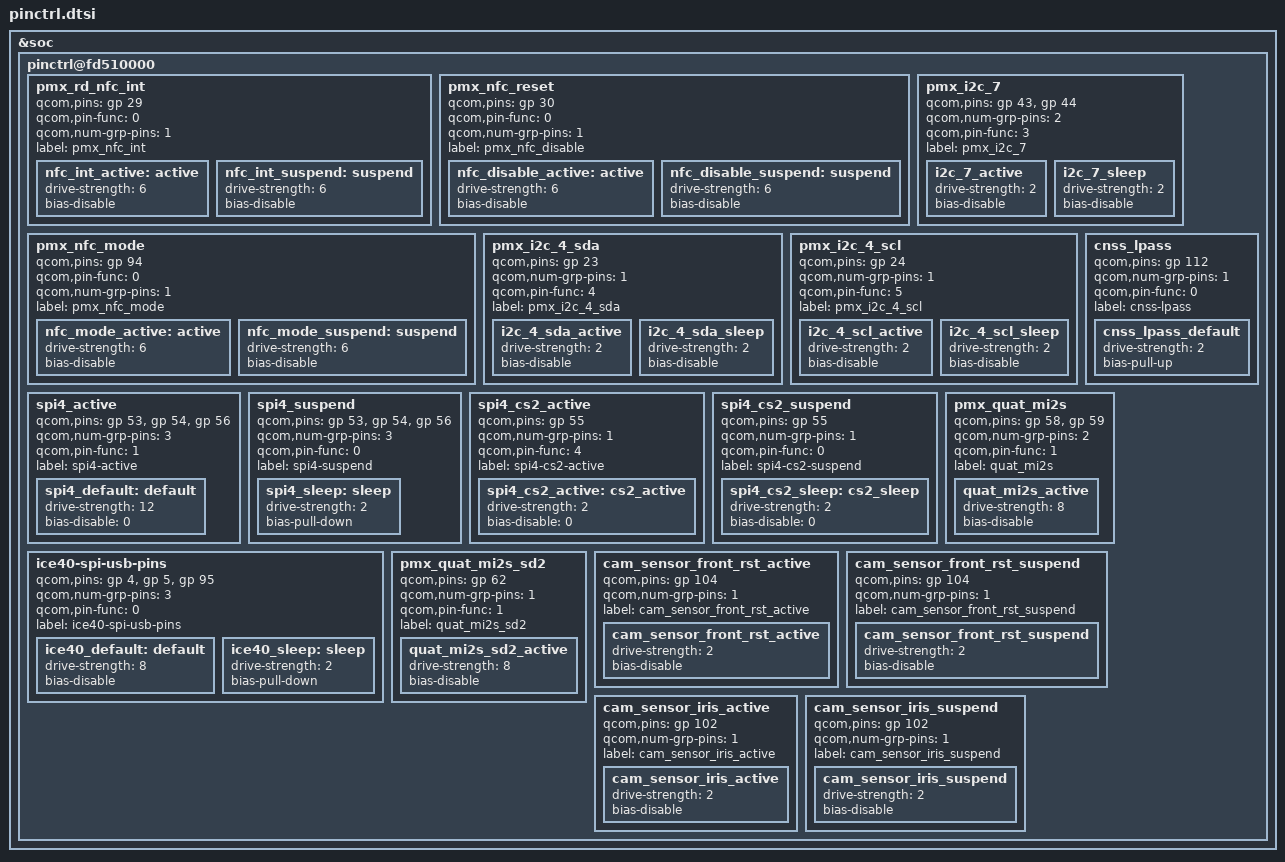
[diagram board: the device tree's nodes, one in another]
&soc {
	pinctrl@fd510000 {

        /* NFC Start */
		pmx_rd_nfc_int{
			qcom,pins = <&gp 29>;
			qcom,pin-func = <0>;
			qcom,num-grp-pins = <1>;
			label = "pmx_nfc_int";

			nfc_int_active: active {
				drive-strength = <6>;
				bias-disable;
			};

			nfc_int_suspend: suspend {
				drive-strength = <6>;
				bias-disable;
			};
		};

		pmx_nfc_reset{
			qcom,pins = <&gp 30>;
			qcom,pin-func = <0>;
			qcom,num-grp-pins = <1>;
			label = "pmx_nfc_disable";

			nfc_disable_active: active {
				drive-strength = <6>;
				bias-disable;
			};

			nfc_disable_suspend: suspend {
				drive-strength = <6>;
				bias-disable;
			};
		};

		pmx_nfc_mode{
			qcom,pins = <&gp 94>;
			qcom,pin-func = <0>;
			qcom,num-grp-pins = <1>;
			label = "pmx_nfc_mode";

			nfc_mode_active: active {
				drive-strength = <6>;
				bias-disable;
			};

			nfc_mode_suspend: suspend {
				drive-strength = <6>;
				bias-disable;
			};
		};
        /* NFC End */

		pmx_i2c_7 {
			qcom,pins = <&gp 43>, <&gp 44>; /* SDA, SCL — BLSP2 I2C1 */
			qcom,num-grp-pins = <2>;
			qcom,pin-func = <3>;
			label = "pmx_i2c_7";
	
			i2c_7_active: i2c_7_active {
				drive-strength = <2>;
				bias-disable;
			};
	
			i2c_7_sleep: i2c_7_sleep {
				drive-strength = <2>;
				bias-disable;
			};
		};

		/*
		 * IMU / mag / baro on BLSP1 QUP5 (mainline blsp1_i2c5).
		 * Unlike GPIO 27/28 and 43/44, these two pins do not share
		 * the same mux index: 23 is func 4, 24 is func 5.
		 * pin-func 3 here is UART/SPI and the chips never ACK.
		 */
		pmx_i2c_4_sda {
			qcom,pins = <&gp 23>;
			qcom,num-grp-pins = <1>;
			qcom,pin-func = <4>;
			label = "pmx_i2c_4_sda";

			i2c_4_sda_active: i2c_4_sda_active {
				drive-strength = <2>;
				bias-disable;
			};

			i2c_4_sda_sleep: i2c_4_sda_sleep {
				drive-strength = <2>;
				bias-disable;
			};
		};

		pmx_i2c_4_scl {
			qcom,pins = <&gp 24>;
			qcom,num-grp-pins = <1>;
			qcom,pin-func = <5>;
			label = "pmx_i2c_4_scl";

			i2c_4_scl_active: i2c_4_scl_active {
				drive-strength = <2>;
				bias-disable;
			};

			i2c_4_scl_sleep: i2c_4_scl_sleep {
				drive-strength = <2>;
				bias-disable;
			};
		};
		cnss_lpass: cnss_lpass {
			qcom,pins = <&gp 112>;
			qcom,num-grp-pins = <1>;
			qcom,pin-func = <0>;
			label = "cnss-lpass";
			/* default state */
			cnss_lpass_default: cnss_lpass_default {
				drive-strength = <2>;
				bias-pull-up;
			};
		};
		
		spi4_active {
			/* MOSI, MISO, CLK */
			qcom,pins = <&gp 53>, <&gp 54>, <&gp 56>;
			qcom,num-grp-pins = <3>;
			qcom,pin-func = <1>;
			label = "spi4-active";
			/* active state */
			spi4_default: default {
				drive-strength = <12>; /* 12 MA */
				bias-disable = <0>; /* No PULL */
			};
		};

		spi4_suspend {
			/* MOSI, MISO, CLK */
			qcom,pins = <&gp 53>, <&gp 54>, <&gp 56>;
			qcom,num-grp-pins = <3>;
			qcom,pin-func = <0>;
			label = "spi4-suspend";
			/* suspended state */
			spi4_sleep: sleep {
				drive-strength = <2>; /* 2 MA */
				bias-pull-down; /* pull down */
			};
		};

		spi4_cs2_active {
			/* CS */
			qcom,pins = <&gp 55>;
			qcom,num-grp-pins = <1>;
			qcom,pin-func = <4>;
			label = "spi4-cs2-active";
			spi4_cs2_active: cs2_active {
				drive-strength = <2>;
				bias-disable = <0>;
			};
		};

		spi4_cs2_suspend {
			/* CS */
			qcom,pins = <&gp 55>;
			qcom,num-grp-pins = <1>;
			qcom,pin-func = <0>;
			label = "spi4-cs2-suspend";
			spi4_cs2_sleep: cs2_sleep {
				drive-strength = <2>;
				bias-disable = <0>;
			};
		};

		ice40-spi-usb-pins {
			qcom,pins = <&gp 4>, <&gp 5>, <&gp 95>;
			qcom,num-grp-pins = <3>;
			qcom,pin-func = <0>;
			label = "ice40-spi-usb-pins";

			/* active state */
			ice40_default: default {
				drive-strength = <8>;
				bias-disable;
			};

			/* sleep state */
			ice40_sleep: sleep {
				drive-strength = <2>;
				bias-pull-down;
			};
		};

		/*
		 * Quaternary MI2S feeds the TAS2553 loudspeaker amplifier.
		 * Only SCK, WS and SD2 are wired to it: SD0/SD1 (60/61) belong
		 * to the touchscreen, and muxing SD3 (63) trips an XPU
		 * violation that hard-resets the device.
		 */
		pmx_quat_mi2s {
			qcom,pins = <&gp 58>, <&gp 59>; /* SCK, WS */
			qcom,num-grp-pins = <2>;
			qcom,pin-func = <1>;
			label = "quat_mi2s";

			quat_mi2s_active: quat_mi2s_active {
				drive-strength = <8>;
				bias-disable;
			};
		};

		pmx_quat_mi2s_sd2 {
			qcom,pins = <&gp 62>; /* SD2, amplifier data in */
			qcom,num-grp-pins = <1>;
			qcom,pin-func = <1>;
			label = "quat_mi2s_sd2";

			quat_mi2s_sd2_active: quat_mi2s_sd2_active {
				drive-strength = <8>;
				bias-disable;
			};
		};

		/*
		 * Front CAM_FRONT_RES_N (schematic GPIO 104). Do not claim
		 * GPIO 105 (MTP standby, not on 4VM_08r).
		 */
		cam_sensor_front_rst_active {
			qcom,pins = <&gp 104>;
			qcom,num-grp-pins = <1>;
			label = "cam_sensor_front_rst_active";

			cam_sensor_front_rst_active: cam_sensor_front_rst_active {
				drive-strength = <2>;
				bias-disable;
			};
		};

		cam_sensor_front_rst_suspend {
			qcom,pins = <&gp 104>;
			qcom,num-grp-pins = <1>;
			label = "cam_sensor_front_rst_suspend";

			cam_sensor_front_rst_suspend: cam_sensor_front_rst_suspend {
				drive-strength = <2>;
				bias-disable;
			};
		};

		/*
		 * Iris IRIS_CAM_RES_N (schematic GPIO 102). GPIO 106 is not
		 * on the drawing. Do not use cam_sensor_rear2 (GPIO 94 = NFC).
		 */
		cam_sensor_iris_active {
			qcom,pins = <&gp 102>;
			qcom,num-grp-pins = <1>;
			label = "cam_sensor_iris_active";

			cam_sensor_iris_active: cam_sensor_iris_active {
				drive-strength = <2>;
				bias-disable;
			};
		};

		cam_sensor_iris_suspend {
			qcom,pins = <&gp 102>;
			qcom,num-grp-pins = <1>;
			label = "cam_sensor_iris_suspend";

			cam_sensor_iris_suspend: cam_sensor_iris_suspend {
				drive-strength = <2>;
				bias-disable;
			};
		};
	};
};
